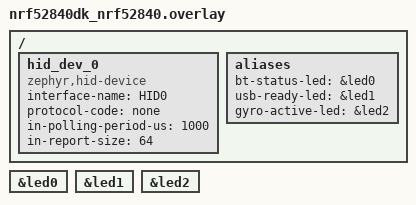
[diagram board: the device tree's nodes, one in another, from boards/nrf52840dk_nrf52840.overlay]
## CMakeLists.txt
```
cmake_minimum_required(VERSION 3.20.0)

list(APPEND BOARD_ROOT ${CMAKE_CURRENT_LIST_DIR})
set(CMAKE_EXPORT_COMPILE_COMMANDS 1)

find_package(Zephyr REQUIRED HINTS $ENV{ZEPHYR_BASE})
project(daydream2hid)


FILE(GLOB app_sources src/*.c)
target_include_directories(app PRIVATE src)
target_sources(app PRIVATE ${app_sources})
```

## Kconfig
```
source "Kconfig.zephyr"

config D2H_USBD_MAX_POWER
    int "USB device sample bMaxPower value"
    default 125
    range 0 250

config D2H_USBD_SELF_POWERED
    bool
    default n

config D2H_USBD_REMOTE_WAKEUP
    bool
    default n

config D2H_DEVICE_PRODUCT
    string "USB device product string"
    default "Daydream2HID"

config D2H_DEVICE_MANUFACTURER
    string "USB device manufacturer string"
    default "Evan Perry Grove"

config D2H_DEVICE_PID
    hex "USB device product ID"
    default 0x0420

config D2H_DEVICE_VID
    hex "USB device vendor ID"
    default 0x2fe3
```

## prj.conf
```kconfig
CONFIG_BT=y
CONFIG_BT_CENTRAL=y
CONFIG_BT_SMP=y
CONFIG_BT_GATT_CLIENT=y

CONFIG_BT_BUF_ACL_RX_SIZE=255
CONFIG_BT_BUF_ACL_TX_SIZE=251
CONFIG_BT_BUF_CMD_TX_SIZE=255
CONFIG_BT_BUF_EVT_DISCARDABLE_SIZE=255
CONFIG_BT_L2CAP_TX_MTU=247

CONFIG_USB_DEVICE_STACK_NEXT=y
CONFIG_USBD_HID_SUPPORT=y
# CONFIG_USB_DEVICE_HID=y
# CONFIG_USB_DEVICE_INITIALIZE_AT_BOOT=n

CONFIG_DEBUG=y
CONFIG_DEBUG_INFO=y
CONFIG_DEBUG_THREAD_INFO=y

CONFIG_USE_SEGGER_RTT=y
CONFIG_LOG=y
CONFIG_CONSOLE=y
CONFIG_RTT_CONSOLE=y
CONFIG_LOG_BACKEND_RTT=y

CONFIG_PRINTK=y

CONFIG_GPIO=y
# CONFIG_INPUT=y
# CONFIG_INPUT_MODE_SYNCHRONOUS=y
```

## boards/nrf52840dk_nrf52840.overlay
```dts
/ {
	hid_dev_0: hid_dev_0 {
		compatible = "zephyr,hid-device";
		interface-name = "HID0";
		protocol-code = "none";
		in-polling-period-us = <1000>;
		in-report-size = <64>;
	};

	aliases {
		bt-status-led = &led0;
		usb-ready-led = &led1;
		gyro-active-led = &led2;
	};
};

&led0 {
	status = "okay";
};

&led1 {
	status = "okay";
};

&led2 {
	status = "okay";
};
```

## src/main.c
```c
#include "main.h"
#include <zephyr/usb/class/usb_hid.h>
#include <zephyr/bluetooth/bluetooth.h>
#include <zephyr/bluetooth/hci.h>
#include <zephyr/bluetooth/conn.h>
#include <zephyr/bluetooth/uuid.h>
#include <zephyr/bluetooth/gatt.h>

#include <string.h>

#include <zephyr/device.h>
#include <zephyr/sys/util.h>

#include <zephyr/logging/log.h>
LOG_MODULE_REGISTER(main, LOG_LEVEL_INF);

int main(void)
{
    int ret;

    ret = boot_leds();
    if (ret < 0) {  
        return 0;
    }

    ret = boot_usb();
    if (ret < 0) {  
        return 0;
    }

    ret = boot_mouse();
    if (ret < 0) {  
        return 0;
    }

    ret = boot_bluetooth();
    if (ret < 0) {  
        return 0;
    }

    while (true) {
        UDC_STATIC_BUF_DEFINE(report, MOUSE_REPORT_COUNT);

        mouse_fetch_hid(report);

        ret = usb_write_hid(report);
        if (ret) {
            LOG_ERR("HID write error, %d", ret);
        } else {
            usb_wait_ep();
        }
    }
    return 0;
}
```

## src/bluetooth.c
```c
#include "main.h"
#include <zephyr/bluetooth/bluetooth.h>
#include <zephyr/bluetooth/hci.h>
#include <zephyr/bluetooth/conn.h>
#include <zephyr/bluetooth/uuid.h>
#include <zephyr/bluetooth/gatt.h>
#include <zephyr/sys/byteorder.h>
#include <zephyr/drivers/gpio.h>


#define MSEC_TO_ISO(msec_) (msec_)

#define CONN_INTERVAL_MIN_MSEC      15
#define CONN_INTERVAL_MAX_MSEC      15
#define CONN_TIMEOUT_MSEC           2000


static void start_scan();
static void on_scan_device_found(
    const bt_addr_le_t *addr, int8_t rssi, uint8_t type,
    struct net_buf_simple *ad);
static void on_connected(struct bt_conn *conn, uint8_t err);
static void on_disconnected(struct bt_conn *conn, uint8_t reason);
static void on_mtu_updated(struct bt_conn *conn, uint16_t tx, uint16_t rx);
static void on_gatt_exchange_mtu(struct bt_conn *conn, uint8_t err,
    struct bt_gatt_exchange_params *params);
static uint8_t on_notify(struct bt_conn *conn,
    struct bt_gatt_subscribe_params *params,
    const void *data, uint16_t length);



static struct bt_conn *open_conn = NULL;
static struct bt_uuid_128 discover_uuid = {};
static struct bt_gatt_discover_params discover_params = {};
static struct bt_gatt_subscribe_params subscribe_params = {};

static const struct gpio_dt_spec bt_status_led = 
    GPIO_DT_SPEC_GET(DT_ALIAS(led0), gpios);
static const struct bt_uuid_16 google_service_uuid = BT_UUID_INIT_16(0xfe55);
static const struct bt_uuid_128 daydream_data_uuid = BT_UUID_INIT_128(
    BT_UUID_128_ENCODE(0x00000001, 0x1000, 0x1000, 0x8000, 0x00805f9b34fb));

BT_CONN_CB_DEFINE(conn_cbs) = {
    .connected = on_connected,
    .disconnected = on_disconnected,
};

static struct bt_gatt_cb gatt_callbacks = {
    .att_mtu_updated = on_mtu_updated
};

static struct bt_gatt_exchange_params mtu_exchange_params = {
    .func = on_gatt_exchange_mtu
};

LOG_MODULE_REGISTER(bluetooth, LOG_LEVEL_INF);


static void start_scan()
{
    int err = bt_le_scan_start(BT_LE_SCAN_ACTIVE, on_scan_device_found);
    if (err) {
        LOG_ERR("bt_le_scan_start: %d", err);
        return;
    }

    led_flash(750, 250, LED_BT_STATUS);

    LOG_INF("Starting scan");
}

static bool is_daydream_controller(struct bt_data *data, void *user_data)
{
    bool *is_daydream = user_data;

    if (data->type != BT_DATA_NAME_COMPLETE) {
        return true;
    }

    char cmp[] = "Daydream controller";
    if (data->data_len != sizeof(cmp) - 1) {
        return false;
    }

    *is_daydream = 0 == memcmp(data->data, cmp, sizeof(cmp) - 1);
    return false;
}

static void on_scan_device_found(
    const bt_addr_le_t *addr, int8_t rssi, uint8_t type,
    struct net_buf_simple *ad)
{
    if (type != BT_GAP_ADV_TYPE_ADV_IND &&
        type != BT_GAP_ADV_TYPE_ADV_DIRECT_IND) {
        return;
    }

    LOG_HEXDUMP_DBG(ad->data, ad->len, "ad");

    bool is_daydream = false;
    bt_data_parse(ad, is_daydream_controller, &is_daydream);

    if (is_daydream) {
        char dev[BT_ADDR_LE_STR_LEN];
        bt_addr_le_to_str(addr, dev, sizeof(dev));
        LOG_INF("Found daydream! %s", dev);
    } else {
        return;
    }

    int err = bt_le_scan_stop();
    if (err) {
        LOG_ERR("bt_le_scan_stop: %d", err);
        return;
    }

    struct bt_conn *conn;
    err = bt_conn_le_create(addr, BT_CONN_LE_CREATE_CONN,
        BT_LE_CONN_PARAM_DEFAULT, &conn);
    if (err) {
        LOG_ERR("bt_conn_le_create: %d", err);
        start_scan();
        return;
    }

    bt_conn_unref(conn);
}

static void set_conn_params(struct k_work *work)
{
    static struct bt_le_conn_param params = BT_LE_CONN_PARAM_INIT(
        BT_GAP_MS_TO_CONN_INTERVAL(CONN_INTERVAL_MIN_MSEC),
        BT_GAP_MS_TO_CONN_INTERVAL(CONN_INTERVAL_MAX_MSEC),
        1,
        BT_GAP_MS_TO_CONN_TIMEOUT(CONN_TIMEOUT_MSEC)
    );
    bt_conn_le_param_update(open_conn, &params);
}
K_WORK_DEFINE(conn_params_work, set_conn_params);

static uint8_t on_notify(struct bt_conn *conn,
   struct bt_gatt_subscribe_params *params,
   const void *data, uint16_t length)
{
    if (!data) {
        return BT_GATT_ITER_STOP;
    } else if (length != DAYDREAM_PKT_SIZE) {
        LOG_HEXDUMP_ERR(data, length, "incorrect packet length");
        return BT_GATT_ITER_STOP;
    }

    LOG_HEXDUMP_DBG(data, length, "notification");

    int err = daydream_queue_pkt(data, K_MSEC(1));
    if (err) {
        LOG_ERR("daydream_queue_pkt: %d", err);
    }

    return BT_GATT_ITER_CONTINUE;
}

static uint8_t on_gatt_svc_discover(struct bt_conn *conn,
    const struct bt_gatt_attr *attr,
    struct bt_gatt_discover_params *params)
{
    if (!attr) {
        return BT_GATT_ITER_STOP;
    }

    int err = 0;

    if (!bt_uuid_cmp(params->uuid, &google_service_uuid.uuid)) {
        LOG_DBG("Discovered service!");
        memcpy(&discover_uuid, &daydream_data_uuid, sizeof(struct bt_uuid_128));
        discover_params.start_handle = attr->handle + 1;
        discover_params.type = BT_GATT_DISCOVER_CHARACTERISTIC;
        err = bt_gatt_discover(conn, &discover_params);
        if (err) {
            LOG_ERR("bt_gatt_discover: %d", err);
        }
    } else if (!bt_uuid_cmp(params->uuid, &daydream_data_uuid.uuid)) {
        LOG_DBG("Discovered characteristic!");
        memcpy(&discover_uuid, BT_UUID_GATT_CCC, sizeof(struct bt_uuid_16));
        discover_params.start_handle = attr->handle + 2;
        discover_params.type = BT_GATT_DISCOVER_DESCRIPTOR;
        subscribe_params.value_handle = bt_gatt_attr_value_handle(attr);
        err = bt_gatt_discover(conn, &discover_params);
        if (err) {
            LOG_ERR("bt_gatt_discover: %d", err);
        }
    } else {
        LOG_DBG("Enabling notification!");
        subscribe_params.notify = on_notify;
        subscribe_params.value = BT_GATT_CCC_NOTIFY;
        subscribe_params.ccc_handle = attr->handle;
        err = bt_gatt_subscribe(conn, &subscribe_params);
        if (err && err != -EALREADY) {
            LOG_ERR("bt_gatt_subscribe: %d", err);
        } else {
            led_off(LED_BT_STATUS);
        }
        k_work_submit(&conn_params_work);
    }

    return BT_GATT_ITER_STOP;
}

static void on_connected(struct bt_conn *conn, uint8_t status)
{
    if (status) {
        LOG_WRN("Error %u", status);
        open_conn = NULL;
        mouse_reset();
        start_scan();
    }

    led_flash(150, 250, LED_BT_STATUS);

    int err;
    open_conn = bt_conn_ref(conn);

    err = bt_gatt_exchange_mtu(open_conn, &mtu_exchange_params);
    if (err) {
        LOG_ERR("bt_gatt_exchange_mtu: %d", err);
    }

    err = bt_conn_set_security(open_conn, BT_SECURITY_L2);
    if (err) {
        LOG_ERR("bt_conn_set_security: %d", err);
    }

    memcpy(&discover_uuid, &google_service_uuid, sizeof(struct bt_uuid_16));
    discover_params.uuid = &discover_uuid.uuid;
    discover_params.func = on_gatt_svc_discover;
    discover_params.start_handle = BT_ATT_FIRST_ATTRIBUTE_HANDLE;
    discover_params.end_handle = BT_ATT_LAST_ATTRIBUTE_HANDLE;
    discover_params.type = BT_GATT_DISCOVER_PRIMARY;
    err = bt_gatt_discover(open_conn, &discover_params);
    if (err) {
        LOG_ERR("bt_gatt_discover: %d", err);
    }
}

static void on_disconnected(struct bt_conn *conn, uint8_t reason)
{
    LOG_WRN("Disconnected %u", reason);
    open_conn = NULL;
    mouse_reset();
    start_scan();
}

static void on_mtu_updated(struct bt_conn *conn, uint16_t tx, uint16_t rx)
{
    LOG_INF("Updated MTU: TX: %d RX: %d bytes\n", tx, rx);
}

static void on_gatt_exchange_mtu(struct bt_conn *conn, uint8_t err,
    struct bt_gatt_exchange_params *params)
{
    LOG_INF("on_gatt_exchange_mtu err=%u", err);
}

int bluetooth_is_connected()
{
    return open_conn != NULL;
}

int boot_bluetooth()
{
    int err;

    led_on(LED_BT_STATUS);

    err = bt_enable(NULL);
    if (err) {
        LOG_ERR("Bluetooth init failed: %d", err);
        return err;
    }

    bt_gatt_cb_register(&gatt_callbacks);

    start_scan();

    return err;
}
```

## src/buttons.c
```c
#include "main.h"

void button_update(int pressed, int duration, struct button_state *state)
{
    if (pressed == state->pressed) {
        state->duration += duration;
    } else {
        state->pressed = pressed;
        state->duration = duration;
    }
}
```

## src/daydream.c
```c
#include "main.h"
#include <zephyr/logging/log.h>
#include <zephyr/sys/__assert.h>
LOG_MODULE_REGISTER(daydream, LOG_LEVEL_DBG);

#define DAYDREAM_THREAD_STACK_SIZE 1024
#define DAYDREAM_THREAD_PRIORITY 0


K_MSGQ_DEFINE(daydream_pkt_queue, DAYDREAM_PKT_SIZE, 8, sizeof(void*));


int daydream_queue_pkt(uint8_t const *pkt, k_timeout_t timeout)
{
    return k_msgq_put(&daydream_pkt_queue, pkt, timeout);
}

static uint32_t decode_inner(uint8_t *pkt, size_t *nbitsp,
    size_t start_byte, size_t start_bit, size_t end_byte, size_t end_bit)
{
    uint32_t result = 0;

    for (size_t i = start_byte; i <= end_byte; ++i) {
        result <<= 8;
        result |= pkt[i];
    }

    uint32_t const nbits = ((end_byte - start_byte) * 8) + start_bit - end_bit;
    uint32_t const mask = (1u << nbits) - 1u;

    __ASSERT(nbits < 32, "decode_inner nbits <= 32");

    if (nbitsp) {
        *nbitsp = nbits;
    }

    result >>= end_bit;
    result &= mask;

    return result;
}

static unsigned decode_unsigned(uint8_t *pkt,
    size_t start_byte, size_t start_bit, size_t end_byte, size_t end_bit)
{
    return decode_inner(pkt, NULL,
        start_byte, start_bit, end_byte, end_bit);
}

static int decode_twos_complement(uint8_t *pkt,
    size_t start_byte, size_t start_bit, size_t end_byte, size_t end_bit)
{
    size_t nbits = 0;
    uint32_t decoded = decode_inner(pkt, &nbits,
        start_byte, start_bit, end_byte, end_bit);

    __ASSERT(nbits > 0, "decode_twos_complement nbits > 0");
    __ASSERT(nbits < 32, "decode_twos_complement nbits < 32");

    uint32_t const signmask = 1u << (nbits - 1);

    int result;

    if (decoded & signmask) {
        uint32_t const mask = (1u << nbits) - 1u;
        // result = 1;
        result = (~decoded & mask);
        result += 1;
        result = -result;
    } else {
        result = decoded;
    }

    return result;
}

static int daydream_decode(void *_a, void *_b, void *_c)
{
    bool has_initial = false;
    unsigned prev_timestamp;

    uint8_t pkt[DAYDREAM_PKT_SIZE];
    struct daydream_pkt decoded = {};
    int err;

    for (;;) {
        err = k_msgq_get(&daydream_pkt_queue, pkt, K_MSEC(500));
        if (!bluetooth_is_connected()) {
            k_msgq_purge(&daydream_pkt_queue);
            continue;
        }

        if (err == -EAGAIN && bluetooth_is_connected()) {
            LOG_WRN("Packet timeout");
            continue;
        } else if (err) {
            LOG_ERR("k_msgq_get: %d", err);
            continue;
        }

        unsigned sqn = decode_unsigned(pkt, 1, 7, 1, 2);
        unsigned timestamp = decode_unsigned(pkt, 0, 8, 1, 7);

        if (has_initial) {
            if ((decoded.sqn + 1) % 32 != sqn) {
                LOG_WRN("Dropped packet? prev_sqn=%u sqn=%u", decoded.sqn, sqn);
            }

            if (timestamp <= prev_timestamp) {
                decoded.duration = 512 - prev_timestamp + timestamp;
            } else {
                decoded.duration = timestamp - prev_timestamp;
            }

            decoded.orient_x = decode_twos_complement(pkt, 1, 2, 3, 5);
            decoded.orient_z = decode_twos_complement(pkt, 3, 5, 4, 0);
            decoded.orient_y = -decode_twos_complement(pkt, 5, 8, 6, 3);

            decoded.accel_x = decode_twos_complement(pkt, 6, 3, 8, 6);
            decoded.accel_z = decode_twos_complement(pkt, 8, 6, 9, 1);
            decoded.accel_y = -decode_twos_complement(pkt, 9, 1, 11, 4);

            decoded.gyro_x = decode_twos_complement(pkt, 11, 4, 13, 7);
            decoded.gyro_z = decode_twos_complement(pkt, 13, 7, 14, 2);
            decoded.gyro_y = -decode_twos_complement(pkt, 14, 2, 16, 5);

            decoded.trackpad_x = decode_unsigned(pkt, 16, 5, 17, 5);
            decoded.trackpad_y = decode_unsigned(pkt, 17, 5, 18, 5);

            decoded.sqn = sqn;

            decoded.vol_up = (pkt[18] & 0x10) != 0;
            decoded.vol_dn = (pkt[18] & 0x08) != 0;
            decoded.app = (pkt[18] & 0x04) != 0;
            decoded.home = (pkt[18] & 0x02) != 0;
            decoded.trackpad_btn = (pkt[18] & 0x01) != 0;

            err = mouse_push_daydream(&decoded);
            if (err) {
                LOG_ERR("mouse_push_daydream: %d", err);
            }
        }

        has_initial = true;
        prev_timestamp = timestamp;
    }

    return 0;
}

K_THREAD_DEFINE(daydream_decode_thread, DAYDREAM_THREAD_STACK_SIZE,
    daydream_decode, NULL, NULL, NULL,
    DAYDREAM_THREAD_PRIORITY, 0, 1);
```

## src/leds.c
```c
#include "main.h"
#include <zephyr/drivers/gpio.h>
#include <zephyr/logging/log.h>

struct led {
    struct gpio_dt_spec led;
    struct k_work work;
    struct k_timer timer;
    int on_msec;
    int off_msec;
};


static struct led leds[LED_COUNT] = {
    [LED_BT_STATUS] = { .led = GPIO_DT_SPEC_GET(DT_ALIAS(bt_status_led), gpios) },
    [LED_USB_READY] = { .led = GPIO_DT_SPEC_GET(DT_ALIAS(usb_ready_led), gpios) },
    [LED_GYRO_ACTIVE] = { .led = GPIO_DT_SPEC_GET(DT_ALIAS(gyro_active_led), gpios) },
};

LOG_MODULE_REGISTER(leds, LOG_LEVEL_DBG);


void led_on(enum led_id id)
{
    leds[id].on_msec = 0;
    k_timer_stop(&leds[id].timer);
    k_work_cancel(&leds[id].work);
    gpio_pin_set_dt(&leds[id].led, 1);
}

void led_off(enum led_id id)
{
    leds[id].on_msec = 0;
    k_timer_stop(&leds[id].timer);
    k_work_cancel(&leds[id].work);
    gpio_pin_set_dt(&leds[id].led, 0);
}

void led_flash(int on_msec, int off_msec, enum led_id id)
{
    leds[id].on_msec = on_msec;
    leds[id].off_msec = off_msec;
    k_work_cancel(&leds[id].work);
    gpio_pin_set_dt(&leds[id].led, 1);
    k_timer_start(&leds[id].timer, K_MSEC(on_msec), K_NO_WAIT);
}

static void led_work_handler(struct k_work *work)
{
    struct led *led = CONTAINER_OF(work, struct led, work);
    if (!led->on_msec) {
        return;
    }

    int interval = gpio_pin_get_dt(&led->led)
        ? led->off_msec
        : led->on_msec;

    LOG_DBG("flash!");

    gpio_pin_toggle_dt(&led->led);
    k_timer_start(&led->timer, K_MSEC(interval), K_NO_WAIT);
}

static void led_timer_handler(struct k_timer *timer)
{
    struct led *led = CONTAINER_OF(timer, struct led, timer);
    k_work_submit(&led->work);
}

static int led_init(struct led *led)
{
    k_work_init(&led->work, led_work_handler);
    k_timer_init(&led->timer, led_timer_handler, NULL);
    led->on_msec = 0;
    led->off_msec = 0;

    if (!gpio_is_ready_dt(&led->led)) {
        LOG_ERR("GPIO device not ready");
        return -EAGAIN;
    }

    return gpio_pin_configure_dt(&led->led, GPIO_OUTPUT_INACTIVE);
}

int boot_leds()
{
    int err = 0;
    for (size_t i = 0; i < LED_COUNT; ++i) {
        err = led_init(&leds[i]);
        if (err) {
            LOG_ERR("led_init[%zu]: %d", i, err);
            return err;
        }
    }

    return err;
}

// static int led_thread_fn(void *_unused0, void *_unused1, void *_unused2)
// {

// }

// K_THREAD_DEFINE(led_thread, LED_THREAD_STACK_SIZE,
//     led_thread_fn, NULL, NULL, NULL,
//     LED_THREAD_PRIORITY, 0, 1);
```

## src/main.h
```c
#pragma once

#include <zephyr/kernel.h>
#include <zephyr/usb/usbd.h>

#define DAYDREAM_PKT_SIZE 20

#define MINMAX(min_, x_, max_) MIN(max_, MAX(min_, x_))

enum scroll_direction {
    SCROLL_NONE,
    SCROLL_UP,
    SCROLL_DOWN,
    SCROLL_LOCK,
};

enum mouse_report_idx {
    MOUSE_BTN_REPORT_IDX,
    MOUSE_X_REPORT_IDX,
    MOUSE_Y_REPORT_IDX,
    MOUSE_WHEEL_REPORT_IDX,
    MOUSE_REPORT_COUNT
};

enum led_id {
    LED_BT_STATUS,
    LED_USB_READY,
    LED_GYRO_ACTIVE,
    LED_COUNT
};

struct daydream_pkt {
    int orient_x;
    int orient_y;
    int orient_z;
    int accel_x;
    int accel_y;
    int accel_z;
    int gyro_x;
    int gyro_y;
    int gyro_z;
    int trackpad_x;
    int trackpad_y;
    int duration;
    uint16_t sqn : 5;
    uint16_t vol_up : 1;
    uint16_t vol_dn : 1;
    uint16_t app : 1;
    uint16_t home : 1;
    uint16_t trackpad_btn : 1;
};

struct scroll_state {
    enum scroll_direction direction;
    int64_t since;
};

struct move_state {
    int64_t since;
};

struct button_state {
    bool pressed;
    int duration;
};


/* buttons */
void button_update(int pressed, int duration, struct button_state *state);

/* daydream */
int daydream_queue_pkt(uint8_t const *pkt, k_timeout_t timeout);

/* leds */
int boot_leds();
void led_on(enum led_id id);
void led_off(enum led_id id);
void led_flash(int on_msec, int off_msec, enum led_id id);

/* mouse */
int boot_mouse();
void mouse_reset();
int mouse_push_daydream(struct daydream_pkt const *pkt);
int mouse_fetch_hid(uint8_t *buf);

/* usb_hid */
int boot_usb();
void usb_rwup_if_suspended();
int usb_write_hid(uint8_t *buf);
int usb_wait_ep();

/* usbd */
struct usbd_context *usbd_init_device(usbd_msg_cb_t msg_cb);

/* bluetooth */
int boot_bluetooth();
int bluetooth_is_connected();
```

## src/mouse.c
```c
#include "main.h"
#include <math.h>
#include <zephyr/logging/log.h>


#define ACCEL_IN_MAX 4096
#define GYRO_IN_MAX 4096
#define TRACKPAD_IN_MAX 255

#define TRACKPAD_ACCELERATION 150
#define TRACKPAD_VELOCITY 2500
#define TRACKPAD_DRAG_DIVISOR 20

#define GYRO_ACCELERATION 20
#define GYRO_VELOCITY 500
#define ACCEL_MIX_VELOCITY 10

#define MOUSE_BTN_LEFT 0
#define MOUSE_BTN_RIGHT 1
#define GRAVITY 550


enum movement_mode {
    MODE_TRACKPAD,
    MODE_GYRO,
};

enum buttons {
    BTN_TRACKPAD,
    BTN_HOME,
    BTN_APP,
    BTN_VDOWN,
    BTN_VUP,
    N_BUTTONS
};

struct trackpad {
    int x;
    int y;
    bool init;
};

struct gyro {
    int x;
    int y;
    bool init;
};


static void mouse_worker_handler(struct k_work *work);
static void mouse_timer_handler(struct k_timer *timer);
static void move_by_trackpad(struct daydream_pkt const *pkt, int8_t *x, int8_t *y);
static void move_by_gyro(struct daydream_pkt const *pkt, int8_t *x, int8_t *y);
static int8_t scroll_velocity(int duration);


LOG_MODULE_REGISTER(mouse, LOG_LEVEL_INF);
K_MSGQ_DEFINE(mouse_hid_queue, MOUSE_REPORT_COUNT, 8, sizeof(void*));

static struct button_state buttons[N_BUTTONS] = {};
static struct trackpad trackpad = {};
static struct gyro gyro = {};

int mouse_push_daydream(struct daydream_pkt const *pkt)
{
    int8_t hid_msg[MOUSE_REPORT_COUNT] = {};

    button_update(pkt->trackpad_btn, pkt->duration, &buttons[BTN_TRACKPAD]);
    button_update(pkt->home, pkt->duration, &buttons[BTN_HOME]);
    button_update(pkt->app, pkt->duration, &buttons[BTN_APP]);
    button_update(pkt->vol_dn, pkt->duration, &buttons[BTN_VDOWN]);
    button_update(pkt->vol_up, pkt->duration, &buttons[BTN_VUP]);


    if (!buttons[BTN_HOME].pressed) {
        led_off(LED_GYRO_ACTIVE);
        move_by_trackpad(pkt, &hid_msg[MOUSE_X_REPORT_IDX], &hid_msg[MOUSE_Y_REPORT_IDX]);
    } else {
        led_on(LED_GYRO_ACTIVE);
        move_by_gyro(pkt, &hid_msg[MOUSE_X_REPORT_IDX], &hid_msg[MOUSE_Y_REPORT_IDX]);
    }

    if (buttons[BTN_VDOWN].pressed && !buttons[BTN_VUP].pressed) {
        hid_msg[MOUSE_WHEEL_REPORT_IDX] = -scroll_velocity(buttons[BTN_VDOWN].duration);
    } else if (buttons[BTN_VUP].pressed && !buttons[BTN_VDOWN].pressed) {
        hid_msg[MOUSE_WHEEL_REPORT_IDX] = scroll_velocity(buttons[BTN_VUP].duration);
    }

    WRITE_BIT(hid_msg[MOUSE_BTN_REPORT_IDX], MOUSE_BTN_LEFT, pkt->trackpad_btn);
    WRITE_BIT(hid_msg[MOUSE_BTN_REPORT_IDX], MOUSE_BTN_RIGHT, pkt->app);

    int err = k_msgq_put(&mouse_hid_queue, hid_msg, K_MSEC(5));
    if (err) {
        LOG_ERR("k_msgq_put: %d", err);
    }
    return err;
}

void mouse_reset()
{
    memset(buttons, 0, sizeof(buttons));
    trackpad.init = 0;
    gyro.init = 0;
    k_msgq_purge(&mouse_hid_queue);
}

static int pythag(int x, int y)
{
    return round(sqrt(x * x + y * y));
}

static void move_by_trackpad(struct daydream_pkt const *pkt, int8_t *x, int8_t *y)
{
    if (pkt->trackpad_x == 0 && pkt->trackpad_y == 0) {
        trackpad.init = false;
        return;
    }

    if (!trackpad.init) {
        trackpad.init = true;
        trackpad.x = pkt->trackpad_x;
        trackpad.y = pkt->trackpad_y;
        *x = *y = 0;
        return;
    }

    int delta_x = pkt->trackpad_x - trackpad.x;
    trackpad.x = pkt->trackpad_x;

    int delta_y = pkt->trackpad_y - trackpad.y;
    trackpad.y = pkt->trackpad_y;

    int cx = trackpad.x - 127;
    int cy = trackpad.y - 127;
    if (pythag(cx, cy) >= 100 && pkt->trackpad_btn) {
        *x = cx / TRACKPAD_DRAG_DIVISOR;
        *y = cy / TRACKPAD_DRAG_DIVISOR;
        return;
    }

    int vx = delta_x * TRACKPAD_VELOCITY;
    int vy = delta_y * TRACKPAD_VELOCITY;

    int ax = delta_x * delta_x * TRACKPAD_ACCELERATION;
    if (delta_x < 0) {
        ax = -ax;
    }

    int ay = delta_y * delta_y * TRACKPAD_ACCELERATION;
    if (delta_y < 0) {
        ay = -ay;
    }

    int velocity_x = (vx + ax) / (pkt->duration * TRACKPAD_IN_MAX);
    int velocity_y = (vy + ay) / (pkt->duration * TRACKPAD_IN_MAX);

    *x = MINMAX(INT8_MIN, velocity_x, INT8_MAX);
    *y = MINMAX(INT8_MIN, velocity_y, INT8_MAX);
    LOG_DBG("track move t=%d x=%d y=%d", pkt->duration, (int)*x, (int)*y);
}

static void move_by_gyro(struct daydream_pkt const *pkt, int8_t *x, int8_t *y)
{
    if (!gyro.init) {
        gyro.init = true;
        gyro.x = 0;
        gyro.y = 0;
        *x = *y = 0;
        return;
    }

    int delta_x = pkt->gyro_z - gyro.x;
    int delta_y = pkt->gyro_x - gyro.y;

    int vx = delta_x * GYRO_VELOCITY;
    int vy = delta_y * GYRO_VELOCITY;

    int ax = delta_x * delta_x * GYRO_ACCELERATION;
    if (delta_x < 0) {
        ax = -ax;
    }

    int ay = delta_y * delta_y * GYRO_ACCELERATION;
    if (delta_y < 0) {
        ay = -ay;
    }

    /* mix in a bit of the accelerometer. this feels a bit more natural to me */
    int accel_x = pkt->accel_x * ACCEL_MIX_VELOCITY / ACCEL_IN_MAX;
    int accel_y = pkt->accel_z * ACCEL_MIX_VELOCITY / ACCEL_IN_MAX;

    int velocity_x = (accel_x - (vx + ax)) / (pkt->duration * GYRO_IN_MAX);
    int velocity_y = (accel_y - (vy + ay)) / (pkt->duration * GYRO_IN_MAX);

    *x = MINMAX(INT8_MIN, velocity_x, INT8_MAX);
    *y = MINMAX(INT8_MIN, velocity_y, INT8_MAX);
    LOG_DBG("gyro move x=%d y=%d", (int)*x, (int)*y);
}

static int8_t scroll_velocity(int duration)
{
    if (duration <= 70) {
        return 1;
    } else if (duration >= 1500) {
        return 5;
    } else if (duration >= 700) {
        return (duration - 500) / 200;
    } else {
        return 0;
    }
}

int boot_mouse()
{
    return 0;
}

int mouse_fetch_hid(uint8_t *buf)
{
    return k_msgq_get(&mouse_hid_queue, buf, K_FOREVER);
}
```

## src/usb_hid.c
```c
/* mostly copied from Zephyr's USB HID example */
#include "main.h"
#include <zephyr/usb/usb_device.h>
#include <zephyr/usb/usbd.h>
#include <zephyr/usb/class/usb_hid.h>

LOG_MODULE_REGISTER(usb_hid);

static const uint8_t hid_report_desc[] = HID_MOUSE_REPORT_DESC(2);
static enum usb_dc_status_code usb_status;

static K_SEM_DEFINE(ep_write_sem, 0, 1);

static inline void status_cb(enum usb_dc_status_code status, const uint8_t *param)
{
    usb_status = status;
}

static void int_in_ready_cb(const struct device *dev)
{
    ARG_UNUSED(dev);
    k_sem_give(&ep_write_sem);
}

void usb_rwup_if_suspended()
{
    if (IS_ENABLED(CONFIG_USB_DEVICE_REMOTE_WAKEUP)) {
        if (usb_status == USB_DC_SUSPEND) {
            usb_wakeup_request();
            return;
        }
    }
}

#if defined(CONFIG_USB_DEVICE_STACK_NEXT)
static int enable_usb_device_next()
{
    struct usbd_context *sample_usbd;
    int err;

    sample_usbd = usbd_init_device(NULL);
    if (sample_usbd == NULL) {
        LOG_ERR("Failed to initialize USB device");
        return -ENODEV;
    }

    err = usbd_enable(sample_usbd);
    if (err) {
        LOG_ERR("Failed to enable device support");
        return err;
    }

    LOG_DBG("USB device support enabled");

    return 0;
}
#endif /* defined(CONFIG_USB_DEVICE_STACK_NEXT) */

static const struct device *hid_dev;
static const struct hid_ops ops = {
    .int_in_ready = int_in_ready_cb,
};

int boot_usb()
{
    int ret;

#if defined(CONFIG_USB_DEVICE_STACK_NEXT)
    hid_dev = DEVICE_DT_GET_ONE(zephyr_hid_device);
#else
    hid_dev = device_get_binding("HID_0");
#endif
    if (hid_dev == NULL) {
        LOG_ERR("Cannot get USB HID Device");
        return -ENOENT;
    }

    usb_hid_register_device(hid_dev,
                hid_report_desc, sizeof(hid_report_desc),
                &ops);

    usb_hid_init(hid_dev);


#if defined(CONFIG_USB_DEVICE_STACK_NEXT)
    ret = enable_usb_device_next();
#else
    ret = usb_enable(status_cb);
#endif
    if (ret != 0) {
        LOG_ERR("Failed to enable USB");
        return ret;
    }

    led_on(LED_USB_READY);

    return ret;
}

int usb_wait_ep()
{
    return k_sem_take(&ep_write_sem, K_FOREVER);
}

int usb_write_hid(uint8_t *buf)
{
    return hid_int_ep_write(hid_dev, buf, MOUSE_REPORT_COUNT, NULL);
}
```

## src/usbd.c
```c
/* this file is mostly copied from Zephyr's usb HID example */
#include "main.h"
#include <stdint.h>

#include <zephyr/device.h>
#include <zephyr/usb/usbd.h>
#include <zephyr/usb/bos.h>

#include <zephyr/logging/log.h>
LOG_MODULE_REGISTER(usbd, LOG_LEVEL_WRN);

/*
 * Instantiate a context named sample_usbd using the default USB device
 * controller, the Zephyr project vendor ID, and the sample product ID.
 * Zephyr project vendor ID must not be used outside of Zephyr samples.
 */
USBD_DEVICE_DEFINE(sample_usbd,
           DEVICE_DT_GET(DT_NODELABEL(zephyr_udc0)),
           CONFIG_D2H_DEVICE_VID, CONFIG_D2H_DEVICE_PID);

USBD_DESC_LANG_DEFINE(sample_lang);
USBD_DESC_MANUFACTURER_DEFINE(sample_mfr, CONFIG_D2H_DEVICE_MANUFACTURER);
USBD_DESC_PRODUCT_DEFINE(sample_product, CONFIG_D2H_DEVICE_PRODUCT);
USBD_DESC_SERIAL_NUMBER_DEFINE(sample_sn);

USBD_DESC_CONFIG_DEFINE(fs_cfg_desc, "FS Configuration");
USBD_DESC_CONFIG_DEFINE(hs_cfg_desc, "HS Configuration");

static const uint8_t attributes = (IS_ENABLED(CONFIG_D2H_USBD_SELF_POWERED) ?
                   USB_SCD_SELF_POWERED : 0) |
                  (IS_ENABLED(CONFIG_D2H_USBD_REMOTE_WAKEUP) ?
                   USB_SCD_REMOTE_WAKEUP : 0);

USBD_CONFIGURATION_DEFINE(sample_fs_config,
              attributes,
              CONFIG_D2H_USBD_MAX_POWER, &fs_cfg_desc);

USBD_CONFIGURATION_DEFINE(sample_hs_config,
              attributes,
              CONFIG_D2H_USBD_MAX_POWER, &hs_cfg_desc);

static void sample_fix_code_triple(struct usbd_context *uds_ctx,
                   const enum usbd_speed speed)
{
    /* Always use class code information from Interface Descriptors */
    if (IS_ENABLED(CONFIG_USBD_CDC_ACM_CLASS) ||
        IS_ENABLED(CONFIG_USBD_CDC_ECM_CLASS) ||
        IS_ENABLED(CONFIG_USBD_CDC_NCM_CLASS) ||
        IS_ENABLED(CONFIG_USBD_AUDIO2_CLASS)) {
        /*
         * Class with multiple interfaces have an Interface
         * Association Descriptor available, use an appropriate triple
         * to indicate it.
         */
        usbd_device_set_code_triple(uds_ctx, speed,
                        USB_BCC_MISCELLANEOUS, 0x02, 0x01);
    } else {
        usbd_device_set_code_triple(uds_ctx, speed, 0, 0, 0);
    }
}

static struct usbd_context *sample_usbd_setup_device(usbd_msg_cb_t msg_cb)
{
    int err;

    err = usbd_add_descriptor(&sample_usbd, &sample_lang);
    if (err) {
        LOG_ERR("Failed to initialize language descriptor (%d)", err);
        return NULL;
    }

    err = usbd_add_descriptor(&sample_usbd, &sample_mfr);
    if (err) {
        LOG_ERR("Failed to initialize manufacturer descriptor (%d)", err);
        return NULL;
    }

    err = usbd_add_descriptor(&sample_usbd, &sample_product);
    if (err) {
        LOG_ERR("Failed to initialize product descriptor (%d)", err);
        return NULL;
    }

    err = usbd_add_descriptor(&sample_usbd, &sample_sn);
    if (err) {
        LOG_ERR("Failed to initialize SN descriptor (%d)", err);
        return NULL;
    }

    if (usbd_caps_speed(&sample_usbd) == USBD_SPEED_HS) {
        err = usbd_add_configuration(&sample_usbd, USBD_SPEED_HS,
                         &sample_hs_config);
        if (err) {
            LOG_ERR("Failed to add High-Speed configuration");
            return NULL;
        }

        err = usbd_register_all_classes(&sample_usbd, USBD_SPEED_HS, 1);
        if (err) {
            LOG_ERR("Failed to add register classes");
            return NULL;
        }

        sample_fix_code_triple(&sample_usbd, USBD_SPEED_HS);
    }

    err = usbd_add_configuration(&sample_usbd, USBD_SPEED_FS,
                     &sample_fs_config);
    if (err) {
        LOG_ERR("Failed to add Full-Speed configuration");
        return NULL;
    }

    err = usbd_register_all_classes(&sample_usbd, USBD_SPEED_FS, 1);
    if (err) {
        LOG_ERR("Failed to add register classes");
        return NULL;
    }

    sample_fix_code_triple(&sample_usbd, USBD_SPEED_FS);

    if (msg_cb != NULL) {
        err = usbd_msg_register_cb(&sample_usbd, msg_cb);
        if (err) {
            LOG_ERR("Failed to register message callback");
            return NULL;
        }
    }

    return &sample_usbd;
}

struct usbd_context *usbd_init_device(usbd_msg_cb_t msg_cb)
{
    int err;

    if (sample_usbd_setup_device(msg_cb) == NULL) {
        return NULL;
    }

    err = usbd_init(&sample_usbd);
    if (err) {
        LOG_ERR("Failed to initialize device support");
        return NULL;
    }

    return &sample_usbd;
}
```
